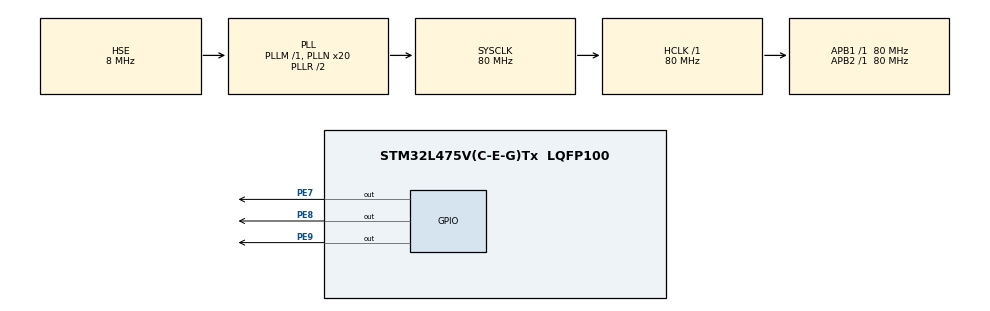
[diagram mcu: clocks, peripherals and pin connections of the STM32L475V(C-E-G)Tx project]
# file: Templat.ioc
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Mcu.Family=STM32L4
Mcu.Name=STM32L475V(C-E-G)Tx
Mcu.Package=LQFP100
NVIC.PriorityGroup=NVIC_PRIORITYGROUP_4
PE7.GPIO_PuPd=GPIO_PULLUP
PE7.GPIO_Speed=GPIO_SPEED_FREQ_HIGH
PE7.PinState=GPIO_PIN_SET
PE7.Signal=GPIO_Output
PE8.GPIO_PuPd=GPIO_PULLUP
PE8.GPIO_Speed=GPIO_SPEED_FREQ_HIGH
PE8.PinState=GPIO_PIN_SET
PE8.Signal=GPIO_Output
PE9.GPIO_ModeDefaultOutputPP=GPIO_MODE_OUTPUT_PP
PE9.GPIO_PuPd=GPIO_PULLUP
PE9.GPIO_Speed=GPIO_SPEED_FREQ_HIGH
PE9.PinState=GPIO_PIN_SET
PE9.Signal=GPIO_Output
PH0-OSC_IN\ (PH0).Mode=HSE-External-Oscillator
PH0-OSC_IN\ (PH0).Signal=RCC_OSC_IN
PH1-OSC_OUT\ (PH1).Mode=HSE-External-Oscillator
PH1-OSC_OUT\ (PH1).Signal=RCC_OSC_OUT
ProjectManager.HeapSize=0x200
ProjectManager.StackSize=0x400
ProjectManager.TargetToolchain=MDK-ARM V5
RCC.ADCFreq_Value=32000000
RCC.AHBFreq_Value=80000000
RCC.APB1Freq_Value=80000000
RCC.APB1TimFreq_Value=80000000
RCC.APB2Freq_Value=80000000
RCC.APB2TimFreq_Value=80000000
RCC.CortexFreq_Value=80000000
RCC.HCLKFreq_Value=80000000
RCC.HSI_VALUE=16000000
RCC.LSE_VALUE=32768
RCC.MSI_VALUE=4000000
RCC.PLLN=20
RCC.PLLSourceVirtual=RCC_PLLSOURCE_HSE
RCC.SYSCLKFreq_VALUE=80000000
RCC.SYSCLKSource=RCC_SYSCLKSOURCE_PLLCLK
RCC.USBFreq_Value=32000000
RCC.VCOOutputFreq_Value=160000000
board=custom

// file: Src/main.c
/**
  ******************************************************************************
  * @file           : main.c
  * @brief          : Main program body
  ******************************************************************************
  ** This notice applies to any and all portions of this file
  * that are not between comment pairs USER CODE BEGIN and
  * USER CODE END. Other portions of this file, whether
  * inserted by the user or by software development tools
  * are owned by their respective copyright owners.
  *
  * COPYRIGHT(c) 2018 STMicroelectronics
  *
  * Redistribution and use in source and binary forms, with or without modification,
  * are permitted provided that the following conditions are met:
  *   1. Redistributions of source code must retain the above copyright notice,
  *      this list of conditions and the following disclaimer.
  *   2. Redistributions in binary form must reproduce the above copyright notice,
  *      this list of conditions and the following disclaimer in the documentation
  *      and/or other materials provided with the distribution.
  *   3. Neither the name of STMicroelectronics nor the names of its contributors
  *      may be used to endorse or promote products derived from this software
  *      without specific prior written permission.
  *
  * THIS SOFTWARE IS PROVIDED BY THE COPYRIGHT HOLDERS AND CONTRIBUTORS "AS IS"
  * AND ANY EXPRESS OR IMPLIED WARRANTIES, INCLUDING, BUT NOT LIMITED TO, THE
  * IMPLIED WARRANTIES OF MERCHANTABILITY AND FITNESS FOR A PARTICULAR PURPOSE ARE
  * DISCLAIMED. IN NO EVENT SHALL THE COPYRIGHT HOLDER OR CONTRIBUTORS BE LIABLE
  * FOR ANY DIRECT, INDIRECT, INCIDENTAL, SPECIAL, EXEMPLARY, OR CONSEQUENTIAL
  * DAMAGES (INCLUDING, BUT NOT LIMITED TO, PROCUREMENT OF SUBSTITUTE GOODS OR
  * SERVICES; LOSS OF USE, DATA, OR PROFITS; OR BUSINESS INTERRUPTION) HOWEVER
  * CAUSED AND ON ANY THEORY OF LIABILITY, WHETHER IN CONTRACT, STRICT LIABILITY,
  * OR TORT (INCLUDING NEGLIGENCE OR OTHERWISE) ARISING IN ANY WAY OUT OF THE USE
  * OF THIS SOFTWARE, EVEN IF ADVISED OF THE POSSIBILITY OF SUCH DAMAGE.
  *
  ******************************************************************************
  */
#include "main.h"
#include "stm32l4xx_hal.h"

/* USER CODE BEGIN Includes */
/* dongos */
#include "main_dos.h"

/* USER CODE END Includes */

/* USER CODE BEGIN PV */
/* Private variables ---------------------------------------------------------*/

/* USER CODE END PV */

void SystemClock_Config(void);
static void MX_GPIO_Init(void);

/* USER CODE BEGIN PFP */
/* Private function prototypes -----------------------------------------------*/

/* USER CODE END PFP */

/* USER CODE BEGIN 0 */
void Delay(__IO uint32_t nCount);
void Delay(__IO uint32_t nCount)
{
    while(nCount--) {};
}
/* USER CODE END 0 */

int main(void)
{

  /* MCU Configuration----------------------------------------------------------*/

  /* Reset of all peripherals, Initializes the Flash interface and the Systick. */
  HAL_Init();

  /* Configure the system clock */
  SystemClock_Config();

  /* Initialize all configured peripherals */
  MX_GPIO_Init();

  /* Infinite loop */
  /* USER CODE BEGIN WHILE */
  /* Initialize the operating system */
  dos_system_init();
  /* Start dongos */
  dos_system_start();

  while (1)
  {

  /* USER CODE END WHILE */

  /* USER CODE BEGIN 3 */
	HAL_GPIO_WritePin(GPIOE, GPIO_PIN_7, GPIO_PIN_SET); 	//PE7 ��1
	HAL_GPIO_WritePin(GPIOE, GPIO_PIN_8, GPIO_PIN_SET); 	//PE8 ��1
	HAL_GPIO_WritePin(GPIOE, GPIO_PIN_9, GPIO_PIN_SET); 	//PE9 ��1
	Delay(0x7FFFFF);
	HAL_GPIO_WritePin(GPIOE, GPIO_PIN_7, GPIO_PIN_RESET);	//PE7 ��0
	HAL_GPIO_WritePin(GPIOE, GPIO_PIN_8, GPIO_PIN_RESET);	//PE8 ��0
	HAL_GPIO_WritePin(GPIOE, GPIO_PIN_9, GPIO_PIN_RESET);	//PE9 ��0
	Delay(0x7FFFFF);
  }
  /* USER CODE END 3 */

}
#if 0 // SYSTEM/sys/sys.c
void SystemClock_Config(void)
{

  RCC_OscInitTypeDef RCC_OscInitStruct;
  RCC_ClkInitTypeDef RCC_ClkInitStruct;

    /**Initializes the CPU, AHB and APB busses clocks
    */
  RCC_OscInitStruct.OscillatorType = RCC_OSCILLATORTYPE_HSE;
  RCC_OscInitStruct.HSEState = RCC_HSE_ON;
  RCC_OscInitStruct.PLL.PLLState = RCC_PLL_ON;
  RCC_OscInitStruct.PLL.PLLSource = RCC_PLLSOURCE_HSE;
  RCC_OscInitStruct.PLL.PLLM = 1;
  RCC_OscInitStruct.PLL.PLLN = 20;
  RCC_OscInitStruct.PLL.PLLP = RCC_PLLP_DIV7;
  RCC_OscInitStruct.PLL.PLLQ = RCC_PLLQ_DIV2;
  RCC_OscInitStruct.PLL.PLLR = RCC_PLLR_DIV2;
  if (HAL_RCC_OscConfig(&RCC_OscInitStruct) != HAL_OK)
  {
    _Error_Handler(__FILE__, __LINE__);
  }

    /**Initializes the CPU, AHB and APB busses clocks
    */
  RCC_ClkInitStruct.ClockType = RCC_CLOCKTYPE_HCLK|RCC_CLOCKTYPE_SYSCLK
                              |RCC_CLOCKTYPE_PCLK1|RCC_CLOCKTYPE_PCLK2;
  RCC_ClkInitStruct.SYSCLKSource = RCC_SYSCLKSOURCE_PLLCLK;
  RCC_ClkInitStruct.AHBCLKDivider = RCC_SYSCLK_DIV1;
  RCC_ClkInitStruct.APB1CLKDivider = RCC_HCLK_DIV1;
  RCC_ClkInitStruct.APB2CLKDivider = RCC_HCLK_DIV1;

  if (HAL_RCC_ClockConfig(&RCC_ClkInitStruct, FLASH_LATENCY_4) != HAL_OK)
  {
    _Error_Handler(__FILE__, __LINE__);
  }

    /**Configure the main internal regulator output voltage
    */
  if (HAL_PWREx_ControlVoltageScaling(PWR_REGULATOR_VOLTAGE_SCALE1) != HAL_OK)
  {
    _Error_Handler(__FILE__, __LINE__);
  }

    /**Configure the Systick interrupt time
    */
  HAL_SYSTICK_Config(HAL_RCC_GetHCLKFreq()/1000);

    /**Configure the Systick
    */
  HAL_SYSTICK_CLKSourceConfig(SYSTICK_CLKSOURCE_HCLK);

  /* SysTick_IRQn interrupt configuration */
  HAL_NVIC_SetPriority(SysTick_IRQn, 0, 0);
}
#endif
/** Configure pins as
        * Analog
        * Input
        * Output
        * EVENT_OUT
        * EXTI
*/
static void MX_GPIO_Init(void)
{

  GPIO_InitTypeDef GPIO_InitStruct;

  /* GPIO Ports Clock Enable */
  __HAL_RCC_GPIOH_CLK_ENABLE();
  __HAL_RCC_GPIOE_CLK_ENABLE();

  /*Configure GPIO pin Output Level */
  HAL_GPIO_WritePin(GPIOE, GPIO_PIN_7|GPIO_PIN_8|GPIO_PIN_9, GPIO_PIN_SET);

  /*Configure GPIO pins : PE7 PE8 PE9 */
  GPIO_InitStruct.Pin = GPIO_PIN_7|GPIO_PIN_8|GPIO_PIN_9;
  GPIO_InitStruct.Mode = GPIO_MODE_OUTPUT_PP;
  GPIO_InitStruct.Pull = GPIO_PULLUP;
  GPIO_InitStruct.Speed = GPIO_SPEED_FREQ_HIGH;
  HAL_GPIO_Init(GPIOE, &GPIO_InitStruct);

}

void _Error_Handler(char *file, int line)
{
  while(1)
  {
  }
}

/************************ (C) COPYRIGHT STMicroelectronics *****END OF FILE****/
